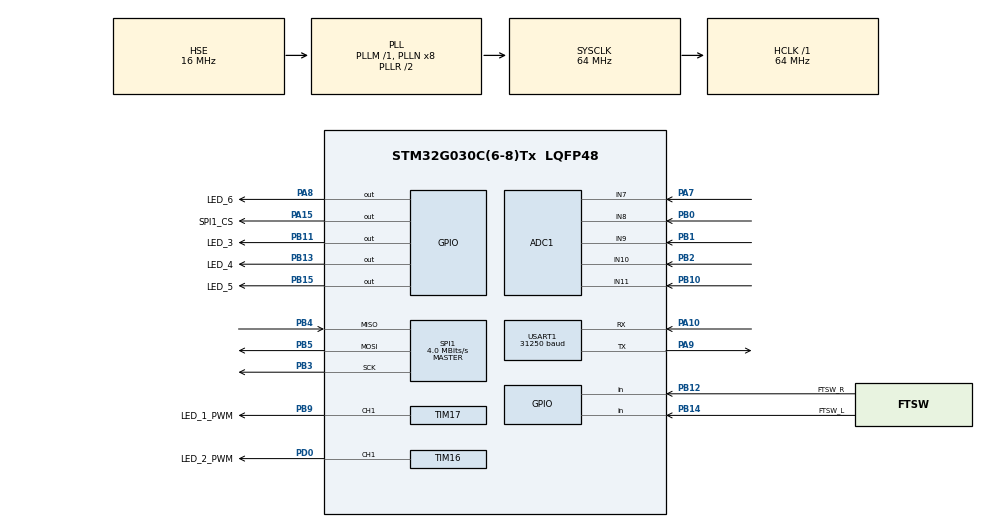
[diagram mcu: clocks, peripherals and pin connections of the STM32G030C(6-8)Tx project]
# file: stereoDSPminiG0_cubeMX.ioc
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ADC1.Channel-0\#ChannelRegularConversion=ADC_CHANNEL_8
ADC1.Channel-1\#ChannelRegularConversion=ADC_CHANNEL_9
ADC1.Channel-2\#ChannelRegularConversion=ADC_CHANNEL_10
ADC1.Channel-3\#ChannelRegularConversion=ADC_CHANNEL_7
ADC1.Channel-4\#ChannelRegularConversion=ADC_CHANNEL_11
ADC1.ClockPrescaler=ADC_CLOCK_ASYNC_DIV1
ADC1.ContinuousConvMode=DISABLE
ADC1.DMAContinuousRequests=ENABLE
ADC1.EOCSelection=ADC_EOC_SEQ_CONV
ADC1.EnableAnalogWatchDog1=false
ADC1.ExternalTrigConv=ADC_EXTERNALTRIG_T1_TRGO2
ADC1.ExternalTrigConvEdge=ADC_EXTERNALTRIGCONVEDGE_RISING
ADC1.NbrOfConversion=5
ADC1.NbrOfConversionFlag=1
ADC1.OversamplingMode=ENABLE
ADC1.Rank-0\#ChannelRegularConversion=1
ADC1.Rank-1\#ChannelRegularConversion=2
ADC1.Rank-2\#ChannelRegularConversion=3
ADC1.Rank-3\#ChannelRegularConversion=4
ADC1.Rank-4\#ChannelRegularConversion=5
ADC1.Ratio=ADC_OVERSAMPLING_RATIO_256
ADC1.RightBitShift=ADC_RIGHTBITSHIFT_8
ADC1.SamplingTime-0\#ChannelRegularConversion=ADC_SAMPLINGTIME_COMMON_1
ADC1.SamplingTime-1\#ChannelRegularConversion=ADC_SAMPLINGTIME_COMMON_1
ADC1.SamplingTime-2\#ChannelRegularConversion=ADC_SAMPLINGTIME_COMMON_1
ADC1.SamplingTime-3\#ChannelRegularConversion=ADC_SAMPLINGTIME_COMMON_1
ADC1.SamplingTime-4\#ChannelRegularConversion=ADC_SAMPLINGTIME_COMMON_1
ADC1.SamplingTimeCommon1=ADC_SAMPLETIME_160CYCLES_5
ADC1.SamplingTimeCommon2=ADC_SAMPLETIME_160CYCLES_5
ADC1.SelectedChannel=ADC_CHANNEL_7|ADC_CHANNEL_8|ADC_CHANNEL_9|ADC_CHANNEL_10|ADC_CHANNEL_11
ADC1.master=1
Dma.ADC1.0.Direction=DMA_PERIPH_TO_MEMORY
Dma.ADC1.0.EventEnable=DISABLE
Dma.ADC1.0.Instance=DMA1_Channel1
Dma.ADC1.0.MemDataAlignment=DMA_MDATAALIGN_HALFWORD
Dma.ADC1.0.MemInc=DMA_MINC_ENABLE
Dma.ADC1.0.Mode=DMA_CIRCULAR
Dma.ADC1.0.PeriphDataAlignment=DMA_PDATAALIGN_HALFWORD
Dma.ADC1.0.PeriphInc=DMA_PINC_DISABLE
Dma.ADC1.0.Polarity=HAL_DMAMUX_REQ_GEN_RISING
Dma.ADC1.0.Priority=DMA_PRIORITY_LOW
Dma.ADC1.0.RequestNumber=1
Dma.ADC1.0.SignalID=NONE
Dma.ADC1.0.SyncEnable=DISABLE
Dma.ADC1.0.SyncPolarity=HAL_DMAMUX_SYNC_NO_EVENT
Dma.ADC1.0.SyncRequestNumber=1
Dma.ADC1.0.SyncSignalID=NONE
Dma.Request0=ADC1
Dma.Request1=SPI1_TX
Dma.Request2=SPI1_RX
Dma.SPI1_RX.2.Direction=DMA_PERIPH_TO_MEMORY
Dma.SPI1_RX.2.EventEnable=DISABLE
Dma.SPI1_RX.2.Instance=DMA1_Channel3
Dma.SPI1_RX.2.MemDataAlignment=DMA_MDATAALIGN_HALFWORD
Dma.SPI1_RX.2.MemInc=DMA_MINC_ENABLE
Dma.SPI1_RX.2.Mode=DMA_NORMAL
Dma.SPI1_RX.2.PeriphDataAlignment=DMA_PDATAALIGN_HALFWORD
Dma.SPI1_RX.2.PeriphInc=DMA_PINC_DISABLE
Dma.SPI1_RX.2.Polarity=HAL_DMAMUX_REQ_GEN_RISING
Dma.SPI1_RX.2.Priority=DMA_PRIORITY_VERY_HIGH
Dma.SPI1_RX.2.RequestNumber=1
Dma.SPI1_RX.2.SignalID=NONE
Dma.SPI1_RX.2.SyncEnable=DISABLE
Dma.SPI1_RX.2.SyncPolarity=HAL_DMAMUX_SYNC_NO_EVENT
Dma.SPI1_RX.2.SyncRequestNumber=1
Dma.SPI1_RX.2.SyncSignalID=NONE
Dma.SPI1_TX.1.Direction=DMA_MEMORY_TO_PERIPH
Dma.SPI1_TX.1.EventEnable=DISABLE
Dma.SPI1_TX.1.Instance=DMA1_Channel2
Dma.SPI1_TX.1.MemDataAlignment=DMA_MDATAALIGN_HALFWORD
Dma.SPI1_TX.1.MemInc=DMA_MINC_ENABLE
Dma.SPI1_TX.1.Mode=DMA_NORMAL
Dma.SPI1_TX.1.PeriphDataAlignment=DMA_PDATAALIGN_HALFWORD
Dma.SPI1_TX.1.PeriphInc=DMA_PINC_DISABLE
Dma.SPI1_TX.1.Polarity=HAL_DMAMUX_REQ_GEN_RISING
Dma.SPI1_TX.1.Priority=DMA_PRIORITY_VERY_HIGH
Dma.SPI1_TX.1.RequestNumber=1
Dma.SPI1_TX.1.SignalID=NONE
Dma.SPI1_TX.1.SyncEnable=DISABLE
Dma.SPI1_TX.1.SyncPolarity=HAL_DMAMUX_SYNC_NO_EVENT
Dma.SPI1_TX.1.SyncRequestNumber=1
Dma.SPI1_TX.1.SyncSignalID=NONE
IWDG.Prescaler=IWDG_PRESCALER_32
IWDG.Reload=255
IWDG.Window=255
Mcu.Family=STM32G0
Mcu.Name=STM32G030C(6-8)Tx
Mcu.Package=LQFP48
NVIC.ADC1_IRQn=true\:1\:0\:true\:false\:true\:true\:true\:true
NVIC.DMA1_Channel1_IRQn=true\:1\:0\:true\:false\:true\:false\:true\:true
NVIC.DMA1_Channel2_3_IRQn=true\:0\:0\:false\:false\:true\:false\:true\:true
NVIC.SPI1_IRQn=true\:1\:0\:true\:false\:true\:true\:true\:true
NVIC.TIM1_CC_IRQn=true\:0\:0\:false\:false\:true\:true\:true\:true
NVIC.USART1_IRQn=true\:0\:0\:false\:false\:true\:true\:true\:true
PA10.Mode=Asynchronous
PA10.Signal=USART1_RX
PA13.Mode=Serial_Wire
PA13.Signal=SYS_SWDIO
PA14-BOOT0.Mode=Serial_Wire
PA14-BOOT0.Signal=SYS_SWCLK
PA15.GPIO_Label=SPI1_CS
PA15.GPIO_ModeDefaultOutputPP=GPIO_MODE_OUTPUT_PP
PA15.GPIO_PuPd=GPIO_NOPULL
PA15.PinState=GPIO_PIN_SET
PA15.Signal=GPIO_Output
PA7.Mode=IN7
PA7.Signal=ADC1_IN7
PA8.GPIO_Label=LED_6
PA8.Signal=GPIO_Output
PA9.Mode=Asynchronous
PA9.Signal=USART1_TX
PB0.Mode=IN8
PB0.Signal=ADC1_IN8
PB1.Mode=IN9
PB1.Signal=ADC1_IN9
PB10.Mode=IN11
PB10.Signal=ADC1_IN11
PB11.GPIO_Label=LED_3
PB11.Signal=GPIO_Output
PB12.GPIO_Label=FTSW_R
PB12.GPIO_PuPd=GPIO_PULLUP
PB12.Signal=GPIO_Input
PB13.GPIO_Label=LED_4
PB13.Signal=GPIO_Output
PB14.GPIO_Label=FTSW_L
PB14.GPIO_PuPd=GPIO_PULLUP
PB14.Signal=GPIO_Input
PB15.GPIO_Label=LED_5
PB15.Signal=GPIO_Output
PB2.Mode=IN10
PB2.Signal=ADC1_IN10
PB3.GPIO_Speed=GPIO_SPEED_FREQ_HIGH
PB3.Mode=Full_Duplex_Master
PB3.Signal=SPI1_SCK
PB4.GPIO_Speed=GPIO_SPEED_FREQ_HIGH
PB4.Mode=Full_Duplex_Master
PB4.Signal=SPI1_MISO
PB5.GPIO_Speed=GPIO_SPEED_FREQ_HIGH
PB5.Mode=Full_Duplex_Master
PB5.Signal=SPI1_MOSI
PB9.GPIO_Label=LED_1_PWM
PB9.Signal=S_TIM17_CH1
PD0.GPIO_Label=LED_2_PWM
PD0.Signal=S_TIM16_CH1
PF0-OSC_IN\ (PF0).Mode=HSE-External-Oscillator
PF0-OSC_IN\ (PF0).Signal=RCC_OSC_IN
PF1-OSC_OUT\ (PF1).Mode=HSE-External-Oscillator
PF1-OSC_OUT\ (PF1).Signal=RCC_OSC_OUT
ProjectManager.HeapSize=0x200
ProjectManager.StackSize=0x400
ProjectManager.TargetToolchain=CMake
RCC.ADCCLockSelection=RCC_ADCCLKSOURCE_PLLADC
RCC.ADCFreq_Value=32000000
RCC.AHBFreq_Value=64000000
RCC.CortexFreq_Value=64000000
RCC.EXTERNAL_CLOCK_VALUE=12288000
RCC.HCLKFreq_Value=64000000
RCC.HSE_VALUE=16000000
RCC.HSI_VALUE=16000000
RCC.LSE_VALUE=32768
RCC.PLLP=RCC_PLLP_DIV4
RCC.PLLSourceVirtual=RCC_PLLSOURCE_HSE
RCC.SYSCLKFreq_VALUE=64000000
RCC.SYSCLKSource=RCC_SYSCLKSOURCE_PLLCLK
RCC.VCOOutputFreq_Value=128000000
SH.S_TIM16_CH1.0=TIM16_CH1,PWM Generation1 CH1
SH.S_TIM17_CH1.0=TIM17_CH1,PWM Generation1 CH1
SPI1.BaudRatePrescaler=SPI_BAUDRATEPRESCALER_16
SPI1.CRCCalculation=SPI_CRCCALCULATION_ENABLE
SPI1.CRCLength=SPI_CRC_LENGTH_16BIT
SPI1.CRCPolynomial=X0+X5+X12
SPI1.CalculateBaudRate=4.0 MBits/s
SPI1.DataSize=SPI_DATASIZE_16BIT
SPI1.Direction=SPI_DIRECTION_2LINES
SPI1.Mode=SPI_MODE_MASTER
SPI1.NSSPMode=SPI_NSS_PULSE_DISABLE
SPI1.VirtualNSS=VM_NSSHARD
SPI1.VirtualType=VM_MASTER
TIM1.Channel-Output\ Compare1\ No\ Output=TIM_CHANNEL_1
TIM1.Channel-Output\ Compare2\ No\ Output=TIM_CHANNEL_2
TIM1.OC1Preload=ENABLE
TIM1.Period=10000-1
TIM1.Prescaler=64-1
TIM1.Pulse-Output\ Compare1\ No\ Output=8000-1
TIM1.Pulse-Output\ Compare2\ No\ Output=6000-1
TIM1.TIM_MasterOutputTrigger2=TIM_TRGO2_UPDATE
TIM16.Channel=TIM_CHANNEL_1
TIM16.Period=256-1
TIM16.Prescaler=1
TIM17.Channel=TIM_CHANNEL_1
TIM17.Period=256-1
TIM17.Prescaler=1
USART1.BaudRate=31250
USART1.FIFOMode=FIFOMODE_DISABLE
USART1.Mode=MODE_RX
USART1.RXFIFOThreshold=RXFIFO_THRESHOLD_FULL
USART1.TXFIFOThreshold=TXFIFO_THRESHOLD_EMPTY
USART1.VirtualMode-Asynchronous=VM_ASYNC
VP_IWDG_VS_IWDG.Mode=IWDG_Activate
VP_TIM16_VS_ClockSourceINT.Mode=Enable_Timer
VP_TIM17_VS_ClockSourceINT.Mode=Enable_Timer
VP_TIM1_VS_ClockSourceINT.Mode=Internal
VP_TIM1_VS_no_output1.Mode=Output Compare1 No Output
VP_TIM1_VS_no_output2.Mode=Output Compare2 No Output
board=custom

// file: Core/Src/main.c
/* USER CODE BEGIN Header */
/**
  ******************************************************************************
  * @file           : main.c
  * @brief          : Main program body
  ******************************************************************************
  * @attention
  *
  * Copyright (c) 2026 STMicroelectronics.
  * All rights reserved.
  *
  * This software is licensed under terms that can be found in the LICENSE file
  * in the root directory of this software component.
  * If no LICENSE file comes with this software, it is provided AS-IS.
  *
  ******************************************************************************
  */
/* USER CODE END Header */
#include "main.h"
#include "adc.h"
#include "dma.h"
#include "iwdg.h"
#include "spi.h"
#include "tim.h"
#include "usart.h"
#include "gpio.h"

/* USER CODE BEGIN Includes */
#include "app.h"
/* USER CODE END Includes */

void SystemClock_Config(void);

int main(void)
{

  /* MCU Configuration--------------------------------------------------------*/

  /* Reset of all peripherals, Initializes the Flash interface and the Systick. */
  HAL_Init();

  /* Configure the system clock */
  SystemClock_Config();

  /* Initialize all configured peripherals */
  MX_GPIO_Init();
  MX_DMA_Init();
  MX_ADC1_Init();
  MX_SPI1_Init();
  MX_USART1_UART_Init();
  MX_TIM16_Init();
  MX_TIM17_Init();
  MX_TIM1_Init();
  MX_IWDG_Init();
  /* USER CODE BEGIN 2 */
  appInit();
  /* USER CODE END 2 */

  /* Infinite loop */
  /* USER CODE BEGIN WHILE */
  while (1)
  {
    appPoll();
    __WFI();
    /* USER CODE END WHILE */

  }
}

void SystemClock_Config(void)
{
  RCC_OscInitTypeDef RCC_OscInitStruct = {0};
  RCC_ClkInitTypeDef RCC_ClkInitStruct = {0};

  /** Configure the main internal regulator output voltage
  */
  HAL_PWREx_ControlVoltageScaling(PWR_REGULATOR_VOLTAGE_SCALE1);

  /** Initializes the RCC Oscillators according to the specified parameters
  * in the RCC_OscInitTypeDef structure.
  */
  RCC_OscInitStruct.OscillatorType = RCC_OSCILLATORTYPE_LSI|RCC_OSCILLATORTYPE_HSE;
  RCC_OscInitStruct.HSEState = RCC_HSE_ON;
  RCC_OscInitStruct.LSIState = RCC_LSI_ON;
  RCC_OscInitStruct.PLL.PLLState = RCC_PLL_ON;
  RCC_OscInitStruct.PLL.PLLSource = RCC_PLLSOURCE_HSE;
  RCC_OscInitStruct.PLL.PLLM = RCC_PLLM_DIV1;
  RCC_OscInitStruct.PLL.PLLN = 8;
  RCC_OscInitStruct.PLL.PLLP = RCC_PLLP_DIV4;
  RCC_OscInitStruct.PLL.PLLR = RCC_PLLR_DIV2;
  if (HAL_RCC_OscConfig(&RCC_OscInitStruct) != HAL_OK)
  {
    Error_Handler();
  }

  /** Initializes the CPU, AHB and APB buses clocks
  */
  RCC_ClkInitStruct.ClockType = RCC_CLOCKTYPE_HCLK|RCC_CLOCKTYPE_SYSCLK
                              |RCC_CLOCKTYPE_PCLK1;
  RCC_ClkInitStruct.SYSCLKSource = RCC_SYSCLKSOURCE_PLLCLK;
  RCC_ClkInitStruct.AHBCLKDivider = RCC_SYSCLK_DIV1;
  RCC_ClkInitStruct.APB1CLKDivider = RCC_HCLK_DIV1;

  if (HAL_RCC_ClockConfig(&RCC_ClkInitStruct, FLASH_LATENCY_2) != HAL_OK)
  {
    Error_Handler();
  }
}

void Error_Handler(void)
{
  __disable_irq();
  while (1)
  {
  }
}
